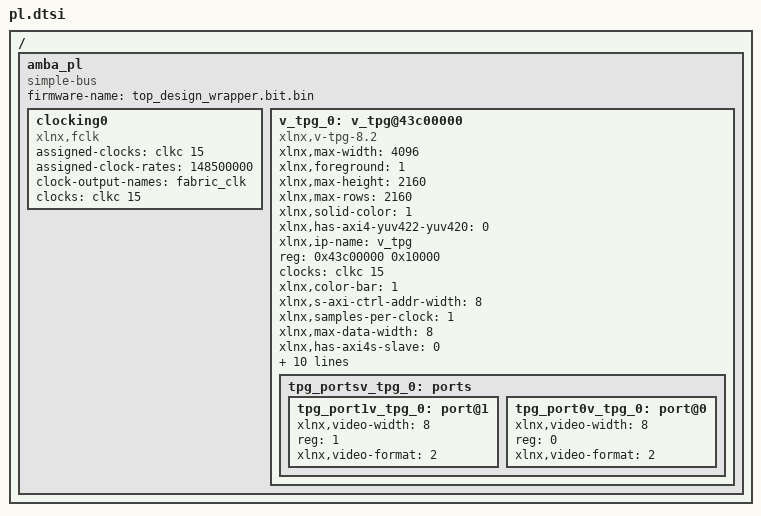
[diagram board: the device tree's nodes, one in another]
/ {
	amba_pl: amba_pl {
		ranges;
		compatible = "simple-bus";
		#address-cells = <1>;
		#size-cells = <1>;
		firmware-name = "top_design_wrapper.bit.bin";
		clocking0: clocking0 {
			compatible = "xlnx,fclk";
			assigned-clocks = <&clkc 15>;
			assigned-clock-rates = <148500000>;
			#clock-cells = <0>;
			clock-output-names = "fabric_clk";
			clocks = <&clkc 15>;
		};
		v_tpg_0: v_tpg@43c00000 {
			compatible = "xlnx,v-tpg-8.2" , "xlnx,v-tpg-8.0";
			xlnx,max-width = <4096>;
			xlnx,foreground = <1>;
			xlnx,max-height = <2160>;
			xlnx,max-rows = <2160>;
			xlnx,solid-color = <1>;
			xlnx,has-axi4-yuv422-yuv420 = <0>;
			xlnx,ip-name = "v_tpg";
			reg = <0x43c00000 0x10000>;
			clocks = <&clkc 15>;
			xlnx,color-bar = <1>;
			xlnx,s-axi-ctrl-addr-width = <8>;
			xlnx,samples-per-clock = <1>;
			xlnx,max-data-width = <8>;
			xlnx,has-axi4s-slave = <0>;
			xlnx,ppc = <1>;
			xlnx,max-cols = <4096>;
			xlnx,edk-iptype = "PERIPHERAL";
			status = "okay";
			clock-names = "ap_clk";
			xlnx,zone-plate = <1>;
			xlnx,num-video-components = <3>;
			xlnx,ramp = <1>;
			xlnx,color-sweep = <1>;
			xlnx,s-axi-ctrl-data-width = <32>;
			xlnx,display-port = <1>;
			xlnx,name = "v_tpg_0";
			tpg_portsv_tpg_0: ports {
				#address-cells = <1>;
				#size-cells = <0>;
				tpg_port1v_tpg_0: port@1 {
					xlnx,video-width = <8>;
					reg = <1>;
					xlnx,video-format = <2>;
				};
				tpg_port0v_tpg_0: port@0 {
					xlnx,video-width = <8>;
					reg = <0>;
					xlnx,video-format = <2>;
				};
			};
		};
	};
};
